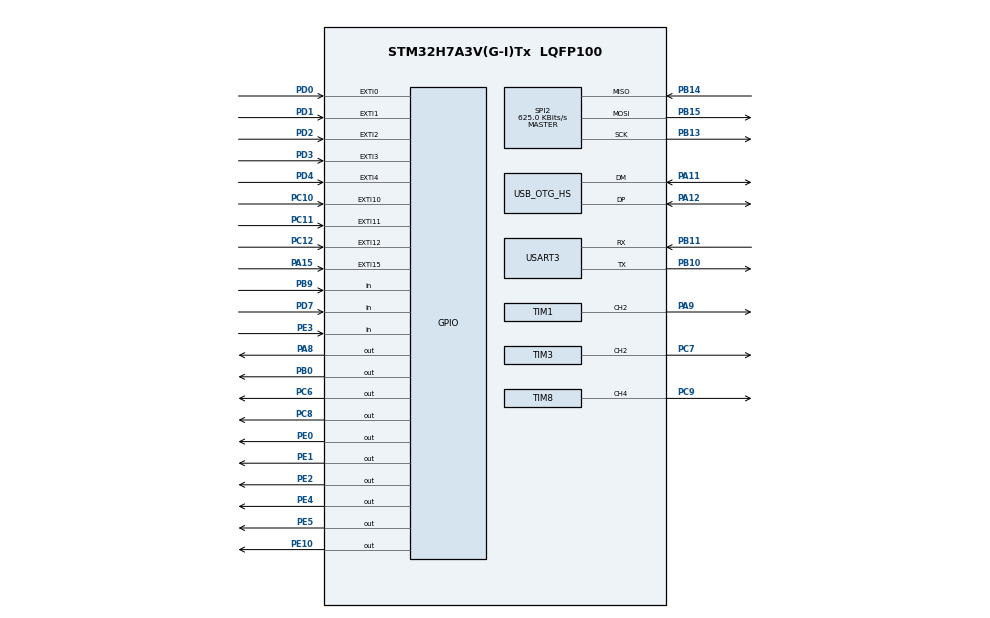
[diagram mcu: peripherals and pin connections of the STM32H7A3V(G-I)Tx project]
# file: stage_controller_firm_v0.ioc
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CORTEX_M7.default_mode_Activation=1
Dma.Request0=TIM1_UP
Dma.Request1=TIM3_UP
Dma.Request2=TIM8_UP
Dma.TIM1_UP.0.Direction=DMA_MEMORY_TO_PERIPH
Dma.TIM1_UP.0.EventEnable=DISABLE
Dma.TIM1_UP.0.FIFOMode=DMA_FIFOMODE_DISABLE
Dma.TIM1_UP.0.Instance=DMA1_Stream0
Dma.TIM1_UP.0.MemDataAlignment=DMA_MDATAALIGN_WORD
Dma.TIM1_UP.0.MemInc=DMA_MINC_ENABLE
Dma.TIM1_UP.0.Mode=DMA_NORMAL
Dma.TIM1_UP.0.PeriphDataAlignment=DMA_PDATAALIGN_WORD
Dma.TIM1_UP.0.PeriphInc=DMA_PINC_DISABLE
Dma.TIM1_UP.0.Polarity=HAL_DMAMUX_REQ_GEN_RISING
Dma.TIM1_UP.0.Priority=DMA_PRIORITY_VERY_HIGH
Dma.TIM1_UP.0.RequestNumber=1
Dma.TIM1_UP.0.SignalID=NONE
Dma.TIM1_UP.0.SyncEnable=DISABLE
Dma.TIM1_UP.0.SyncPolarity=HAL_DMAMUX_SYNC_NO_EVENT
Dma.TIM1_UP.0.SyncRequestNumber=1
Dma.TIM1_UP.0.SyncSignalID=NONE
Dma.TIM3_UP.1.Direction=DMA_MEMORY_TO_PERIPH
Dma.TIM3_UP.1.EventEnable=DISABLE
Dma.TIM3_UP.1.FIFOMode=DMA_FIFOMODE_DISABLE
Dma.TIM3_UP.1.Instance=DMA1_Stream1
Dma.TIM3_UP.1.MemDataAlignment=DMA_MDATAALIGN_WORD
Dma.TIM3_UP.1.MemInc=DMA_MINC_ENABLE
Dma.TIM3_UP.1.Mode=DMA_NORMAL
Dma.TIM3_UP.1.PeriphDataAlignment=DMA_PDATAALIGN_WORD
Dma.TIM3_UP.1.PeriphInc=DMA_PINC_DISABLE
Dma.TIM3_UP.1.Polarity=HAL_DMAMUX_REQ_GEN_RISING
Dma.TIM3_UP.1.Priority=DMA_PRIORITY_VERY_HIGH
Dma.TIM3_UP.1.RequestNumber=1
Dma.TIM3_UP.1.SignalID=NONE
Dma.TIM3_UP.1.SyncEnable=DISABLE
Dma.TIM3_UP.1.SyncPolarity=HAL_DMAMUX_SYNC_NO_EVENT
Dma.TIM3_UP.1.SyncRequestNumber=1
Dma.TIM3_UP.1.SyncSignalID=NONE
Dma.TIM8_UP.2.Direction=DMA_MEMORY_TO_PERIPH
Dma.TIM8_UP.2.EventEnable=DISABLE
Dma.TIM8_UP.2.FIFOMode=DMA_FIFOMODE_DISABLE
Dma.TIM8_UP.2.Instance=DMA1_Stream2
Dma.TIM8_UP.2.MemDataAlignment=DMA_MDATAALIGN_WORD
Dma.TIM8_UP.2.MemInc=DMA_MINC_ENABLE
Dma.TIM8_UP.2.Mode=DMA_NORMAL
Dma.TIM8_UP.2.PeriphDataAlignment=DMA_PDATAALIGN_WORD
Dma.TIM8_UP.2.PeriphInc=DMA_PINC_DISABLE
Dma.TIM8_UP.2.Polarity=HAL_DMAMUX_REQ_GEN_RISING
Dma.TIM8_UP.2.Priority=DMA_PRIORITY_VERY_HIGH
Dma.TIM8_UP.2.RequestNumber=1
Dma.TIM8_UP.2.SignalID=NONE
Dma.TIM8_UP.2.SyncEnable=DISABLE
Dma.TIM8_UP.2.SyncPolarity=HAL_DMAMUX_SYNC_NO_EVENT
Dma.TIM8_UP.2.SyncRequestNumber=1
Dma.TIM8_UP.2.SyncSignalID=NONE
Mcu.Family=STM32H7
Mcu.Name=STM32H7A3V(G-I)Tx
Mcu.Package=LQFP100
NVIC.DMA1_Stream0_IRQn=true\:2\:0\:true\:false\:true\:false\:true\:true
NVIC.DMA1_Stream1_IRQn=true\:2\:0\:true\:false\:true\:false\:true\:true
NVIC.DMA1_Stream2_IRQn=true\:2\:0\:true\:false\:true\:false\:true\:true
NVIC.EXTI0_IRQn=true\:1\:0\:true\:false\:true\:true\:true\:true
NVIC.EXTI15_10_IRQn=true\:1\:0\:true\:false\:true\:true\:true\:true
NVIC.EXTI1_IRQn=true\:1\:0\:true\:false\:true\:true\:true\:true
NVIC.EXTI2_IRQn=true\:1\:0\:true\:false\:true\:true\:true\:true
NVIC.EXTI3_IRQn=true\:1\:0\:true\:false\:true\:true\:true\:true
NVIC.EXTI4_IRQn=true\:1\:0\:true\:false\:true\:true\:true\:true
NVIC.OTG_HS_IRQn=true\:0\:0\:false\:false\:true\:false\:true\:true
NVIC.PriorityGroup=NVIC_PRIORITYGROUP_4
NVIC.TIM1_UP_IRQn=true\:2\:0\:true\:false\:true\:true\:true\:true
NVIC.TIM3_IRQn=true\:2\:0\:true\:false\:true\:true\:true\:true
NVIC.TIM6_DAC_IRQn=true\:3\:0\:true\:false\:true\:true\:true\:true
NVIC.TIM8_UP_TIM13_IRQn=true\:2\:0\:true\:false\:true\:true\:true\:true
NVIC.USART3_IRQn=true\:7\:0\:true\:false\:true\:true\:true\:true
PA11.Mode=Device_Only_FS
PA11.Signal=USB_OTG_HS_DM
PA12.Mode=Device_Only_FS
PA12.Signal=USB_OTG_HS_DP
PA13.Mode=Serial_Wire
PA13.Signal=DEBUG_JTMS-SWDIO
PA14.Mode=Serial_Wire
PA14.Signal=DEBUG_JTCK-SWCLK
PA15.GPIO_ModeDefaultEXTI=GPIO_MODE_IT_RISING_FALLING
PA15.GPIO_PuPd=GPIO_PULLUP
PA15.Signal=GPXTI15
PA8.Signal=GPIO_Output
PA9.Signal=S_TIM1_CH2
PB0.Signal=GPIO_Output
PB10.Mode=Asynchronous
PB10.Signal=USART3_TX
PB11.Mode=Asynchronous
PB11.Signal=USART3_RX
PB13.Mode=Full_Duplex_Master
PB13.Signal=SPI2_SCK
PB14.Mode=Full_Duplex_Master
PB14.Signal=SPI2_MISO
PB15.Mode=Full_Duplex_Master
PB15.Signal=SPI2_MOSI
PB9.Signal=GPIO_Input
PC10.GPIO_ModeDefaultEXTI=GPIO_MODE_IT_RISING_FALLING
PC10.GPIO_PuPd=GPIO_PULLUP
PC10.Signal=GPXTI10
PC11.GPIO_ModeDefaultEXTI=GPIO_MODE_IT_RISING_FALLING
PC11.GPIO_PuPd=GPIO_PULLUP
PC11.Signal=GPXTI11
PC12.GPIO_ModeDefaultEXTI=GPIO_MODE_IT_RISING_FALLING
PC12.GPIO_PuPd=GPIO_PULLUP
PC12.Signal=GPXTI12
PC6.Signal=GPIO_Output
PC7.Signal=S_TIM3_CH2
PC8.Signal=GPIO_Output
PC9.Signal=S_TIM8_CH4
PD0.GPIO_ModeDefaultEXTI=GPIO_MODE_IT_RISING_FALLING
PD0.GPIO_PuPd=GPIO_PULLUP
PD0.Signal=GPXTI0
PD1.GPIO_ModeDefaultEXTI=GPIO_MODE_IT_RISING_FALLING
PD1.GPIO_PuPd=GPIO_PULLUP
PD1.Signal=GPXTI1
PD2.GPIO_ModeDefaultEXTI=GPIO_MODE_IT_RISING_FALLING
PD2.GPIO_PuPd=GPIO_PULLUP
PD2.Signal=GPXTI2
PD3.GPIO_ModeDefaultEXTI=GPIO_MODE_IT_RISING_FALLING
PD3.GPIO_PuPd=GPIO_PULLUP
PD3.Signal=GPXTI3
PD4.GPIO_ModeDefaultEXTI=GPIO_MODE_IT_RISING_FALLING
PD4.GPIO_PuPd=GPIO_PULLUP
PD4.Signal=GPXTI4
PD7.Signal=GPIO_Input
PE0.Signal=GPIO_Output
PE1.Signal=GPIO_Output
PE10.Signal=GPIO_Output
PE2.Signal=GPIO_Output
PE3.Signal=GPIO_Input
PE4.Signal=GPIO_Output
PE5.Signal=GPIO_Output
PH0-OSC_IN.Mode=HSE-External-Clock-Source
PH0-OSC_IN.Signal=RCC_OSC_IN
ProjectManager.HeapSize=0x200
ProjectManager.StackSize=0x400
ProjectManager.TargetToolchain=STM32CubeIDE
RCC.ADCFreq_Value=50390625
RCC.APB1Freq_Value=140000000
RCC.APB2Freq_Value=140000000
RCC.APB3Freq_Value=140000000
RCC.APB4Freq_Value=140000000
RCC.CDPPRE=RCC_APB3_DIV2
RCC.CDPPRE1=RCC_APB1_DIV2
RCC.CDPPRE2=RCC_APB2_DIV2
RCC.CortexFreq_Value=280000000
RCC.DIVM1=5
RCC.DIVN1=112
RCC.DIVQ1=14
RCC.HCLKFreq_Value=280000000
RCC.HSE_VALUE=25000000
RCC.PLLSourceVirtual=RCC_PLLSOURCE_HSE
RCC.SRDPPRE=RCC_APB4_DIV2
RCC.SYSCLKFreq_VALUE=280000000
RCC.SYSCLKSource=RCC_SYSCLKSOURCE_PLLCLK
RCC.USBCLockSelection=RCC_USBCLKSOURCE_HSI48
RCC.USBFreq_Value=48000000
SH.S_TIM1_CH2.0=TIM1_CH2,PWM Generation2 CH2
SH.S_TIM3_CH2.0=TIM3_CH2,PWM Generation2 CH2
SH.S_TIM8_CH4.0=TIM8_CH4,PWM Generation4 CH4
SPI2.BaudRatePrescaler=SPI_BAUDRATEPRESCALER_64
SPI2.CLKPhase=SPI_PHASE_2EDGE
SPI2.CLKPolarity=SPI_POLARITY_HIGH
SPI2.CalculateBaudRate=625.0 KBits/s
SPI2.DataSize=SPI_DATASIZE_8BIT
SPI2.Direction=SPI_DIRECTION_2LINES
SPI2.Mode=SPI_MODE_MASTER
SPI2.VirtualType=VM_MASTER
TIM1.Channel-PWM\ Generation2\ CH2=TIM_CHANNEL_2
TIM1.Prescaler=279
TIM1.TIM_MasterSlaveMode=TIM_MASTERSLAVEMODE_DISABLE
TIM3.Channel-PWM\ Generation2\ CH2=TIM_CHANNEL_2
TIM3.Prescaler=139
TIM8.Channel-PWM\ Generation4\ CH4=TIM_CHANNEL_4
TIM8.Prescaler=279
USART3.VirtualMode-Asynchronous=VM_ASYNC
USB_DEVICE.CLASS_NAME_HS=CDC
USB_DEVICE.VirtualMode=Cdc
USB_DEVICE.VirtualModeHS=Cdc_HS
USB_OTG_HS.VirtualMode-Device_Only_FS=Device_Only_FS
VP_MEMORYMAP_VS_MEMORYMAP.Mode=CurAppReg
VP_TIM1_VS_ClockSourceINT.Mode=Internal
VP_TIM3_VS_ClockSourceINT.Mode=Internal
VP_TIM6_VS_ClockSourceINT.Mode=Enable_Timer
VP_TIM8_VS_ClockSourceINT.Mode=Internal
VP_USB_DEVICE_VS_USB_DEVICE_CDC_HS.Mode=CDC_HS
board=custom

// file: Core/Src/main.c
/* USER CODE BEGIN Header */
/**
  ******************************************************************************
  * @file           : main.c
  * @brief          : Main program body
  ******************************************************************************
  * @attention
  *
  * Copyright (c) 2026 STMicroelectronics.
  * All rights reserved.
  *
  * This software is licensed under terms that can be found in the LICENSE file
  * in the root directory of this software component.
  * If no LICENSE file comes with this software, it is provided AS-IS.
  *
  ******************************************************************************
  */
/* USER CODE END Header */
#include "main.h"
#include "usb_device.h"

/* USER CODE BEGIN Includes */
#include "functions.h"
#include "mtd415t.h"
/* USER CODE END Includes */

SPI_HandleTypeDef hspi2;

TIM_HandleTypeDef htim1;
TIM_HandleTypeDef htim3;
TIM_HandleTypeDef htim6;
TIM_HandleTypeDef htim8;
DMA_HandleTypeDef hdma_tim1_up;
DMA_HandleTypeDef hdma_tim3_up;
DMA_HandleTypeDef hdma_tim8_up;

UART_HandleTypeDef huart3;

void SystemClock_Config(void);
static void MPU_Config(void);
static void MX_GPIO_Init(void);
static void MX_DMA_Init(void);
static void MX_SPI2_Init(void);
static void MX_TIM1_Init(void);
static void MX_TIM3_Init(void);
static void MX_TIM8_Init(void);
static void MX_TIM6_Init(void);
static void MX_USART3_UART_Init(void);

int main(void)
{

  /* MPU Configuration--------------------------------------------------------*/
  MPU_Config();

  /* MCU Configuration--------------------------------------------------------*/

  /* Reset of all peripherals, Initializes the Flash interface and the Systick. */
  HAL_Init();

  /* Configure the system clock */
  SystemClock_Config();

  /* Initialize all configured peripherals */
  MX_GPIO_Init();
  MX_DMA_Init();
  MX_SPI2_Init();
  MX_TIM1_Init();
  MX_TIM3_Init();
  MX_USB_DEVICE_Init();
  MX_TIM8_Init();
  MX_TIM6_Init();
  MX_USART3_UART_Init();
  /* USER CODE BEGIN 2 */

  Motor_Init();
  GetCLK();

  /* MTD415T TEC controller: bind USART3 and start interrupt RX.
   * Requires USART3 to be enabled in CubeMX (115200-8-N-1, global IRQ on),
   * which generates `huart3` and MX_USART3_UART_Init() above. */
  MTD415T_Init(&huart3);

  /* ── Parameter initialisation ──
   * 1. Reg_prepare() fills parm[] with names and default values.
   * 2. Parm_Flash_Load() overwrites parm[] with saved data when valid.
   *    If flash is blank or corrupt the defaults from Reg_prepare() remain.
   * 3. Parm_set() always runs, applying whichever values are in parm[].
   */
  Reg_prepare();
  (void)Parm_Flash_Load();
  Parm_set();

  /* ── TIM6: 10 ms tick  (APB1 timer = 140 MHz, PSC=1399, ARR=999 → 100 Hz) */
  htim6.Instance->PSC = 1399u;
  htim6.Instance->ARR = 999u;
  htim6.Instance->EGR = TIM_EGR_UG;

  /* NVIC は CubeMX で設定（DMA1_Stream0/1/2, TIM1_UP, TIM8_UP_TIM13, TIM3, TIM6_DAC,
   * EXTI）。ここでは TIM6 の更新割り込みを開始するのみ。*/
  HAL_TIM_Base_Start_IT(&htim6);

  /* USER CODE END 2 */

  /* Infinite loop */
  while (1)
  {

    /* USER CODE BEGIN 3 */
    Cmd_Process();
  }
  /* USER CODE END 3 */
}

void SystemClock_Config(void)
{
  RCC_OscInitTypeDef RCC_OscInitStruct = {0};
  RCC_ClkInitTypeDef RCC_ClkInitStruct = {0};

  /*AXI clock gating */
  RCC->CKGAENR = 0xE003FFFF;

  /** Supply configuration update enable
  */
  HAL_PWREx_ConfigSupply(PWR_LDO_SUPPLY);

  /** Configure the main internal regulator output voltage
  */
  __HAL_PWR_VOLTAGESCALING_CONFIG(PWR_REGULATOR_VOLTAGE_SCALE0);

  while(!__HAL_PWR_GET_FLAG(PWR_FLAG_VOSRDY)) {}

  /** Initializes the RCC Oscillators according to the specified parameters
  * in the RCC_OscInitTypeDef structure.
  */
  RCC_OscInitStruct.OscillatorType = RCC_OSCILLATORTYPE_HSI48|RCC_OSCILLATORTYPE_HSE;
  RCC_OscInitStruct.HSEState = RCC_HSE_BYPASS;
  RCC_OscInitStruct.HSI48State = RCC_HSI48_ON;
  RCC_OscInitStruct.PLL.PLLState = RCC_PLL_ON;
  RCC_OscInitStruct.PLL.PLLSource = RCC_PLLSOURCE_HSE;
  RCC_OscInitStruct.PLL.PLLM = 5;
  RCC_OscInitStruct.PLL.PLLN = 112;
  RCC_OscInitStruct.PLL.PLLP = 2;
  RCC_OscInitStruct.PLL.PLLQ = 14;
  RCC_OscInitStruct.PLL.PLLR = 2;
  RCC_OscInitStruct.PLL.PLLRGE = RCC_PLL1VCIRANGE_2;
  RCC_OscInitStruct.PLL.PLLVCOSEL = RCC_PLL1VCOWIDE;
  RCC_OscInitStruct.PLL.PLLFRACN = 0;
  if (HAL_RCC_OscConfig(&RCC_OscInitStruct) != HAL_OK)
  {
    Error_Handler();
  }

  /** Initializes the CPU, AHB and APB buses clocks
  */
  RCC_ClkInitStruct.ClockType = RCC_CLOCKTYPE_HCLK|RCC_CLOCKTYPE_SYSCLK
                              |RCC_CLOCKTYPE_PCLK1|RCC_CLOCKTYPE_PCLK2
                              |RCC_CLOCKTYPE_D3PCLK1|RCC_CLOCKTYPE_D1PCLK1;
  RCC_ClkInitStruct.SYSCLKSource = RCC_SYSCLKSOURCE_PLLCLK;
  RCC_ClkInitStruct.SYSCLKDivider = RCC_SYSCLK_DIV1;
  RCC_ClkInitStruct.AHBCLKDivider = RCC_HCLK_DIV1;
  RCC_ClkInitStruct.APB3CLKDivider = RCC_APB3_DIV2;
  RCC_ClkInitStruct.APB1CLKDivider = RCC_APB1_DIV2;
  RCC_ClkInitStruct.APB2CLKDivider = RCC_APB2_DIV2;
  RCC_ClkInitStruct.APB4CLKDivider = RCC_APB4_DIV2;

  if (HAL_RCC_ClockConfig(&RCC_ClkInitStruct, FLASH_LATENCY_6) != HAL_OK)
  {
    Error_Handler();
  }
}

static void MX_SPI2_Init(void)
{

  /* SPI2 parameter configuration*/
  hspi2.Instance = SPI2;
  hspi2.Init.Mode = SPI_MODE_MASTER;
  hspi2.Init.Direction = SPI_DIRECTION_2LINES;
  hspi2.Init.DataSize = SPI_DATASIZE_8BIT;
  hspi2.Init.CLKPolarity = SPI_POLARITY_HIGH;
  hspi2.Init.CLKPhase = SPI_PHASE_2EDGE;
  hspi2.Init.NSS = SPI_NSS_SOFT;
  hspi2.Init.BaudRatePrescaler = SPI_BAUDRATEPRESCALER_64;
  hspi2.Init.FirstBit = SPI_FIRSTBIT_MSB;
  hspi2.Init.TIMode = SPI_TIMODE_DISABLE;
  hspi2.Init.CRCCalculation = SPI_CRCCALCULATION_DISABLE;
  hspi2.Init.CRCPolynomial = 0x0;
  hspi2.Init.NSSPMode = SPI_NSS_PULSE_ENABLE;
  hspi2.Init.NSSPolarity = SPI_NSS_POLARITY_LOW;
  hspi2.Init.FifoThreshold = SPI_FIFO_THRESHOLD_01DATA;
  hspi2.Init.TxCRCInitializationPattern = SPI_CRC_INITIALIZATION_ALL_ZERO_PATTERN;
  hspi2.Init.RxCRCInitializationPattern = SPI_CRC_INITIALIZATION_ALL_ZERO_PATTERN;
  hspi2.Init.MasterSSIdleness = SPI_MASTER_SS_IDLENESS_00CYCLE;
  hspi2.Init.MasterInterDataIdleness = SPI_MASTER_INTERDATA_IDLENESS_00CYCLE;
  hspi2.Init.MasterReceiverAutoSusp = SPI_MASTER_RX_AUTOSUSP_DISABLE;
  hspi2.Init.MasterKeepIOState = SPI_MASTER_KEEP_IO_STATE_DISABLE;
  hspi2.Init.IOSwap = SPI_IO_SWAP_DISABLE;
  if (HAL_SPI_Init(&hspi2) != HAL_OK)
  {
    Error_Handler();
  }

}

static void MX_TIM1_Init(void)
{

  TIM_ClockConfigTypeDef sClockSourceConfig = {0};
  TIM_MasterConfigTypeDef sMasterConfig = {0};
  TIM_OC_InitTypeDef sConfigOC = {0};
  TIM_BreakDeadTimeConfigTypeDef sBreakDeadTimeConfig = {0};

  htim1.Instance = TIM1;
  htim1.Init.Prescaler = 279;
  htim1.Init.CounterMode = TIM_COUNTERMODE_UP;
  htim1.Init.Period = 65535;
  htim1.Init.ClockDivision = TIM_CLOCKDIVISION_DIV1;
  htim1.Init.RepetitionCounter = 0;
  htim1.Init.AutoReloadPreload = TIM_AUTORELOAD_PRELOAD_DISABLE;
  if (HAL_TIM_Base_Init(&htim1) != HAL_OK)
  {
    Error_Handler();
  }
  sClockSourceConfig.ClockSource = TIM_CLOCKSOURCE_INTERNAL;
  if (HAL_TIM_ConfigClockSource(&htim1, &sClockSourceConfig) != HAL_OK)
  {
    Error_Handler();
  }
  if (HAL_TIM_PWM_Init(&htim1) != HAL_OK)
  {
    Error_Handler();
  }
  sMasterConfig.MasterOutputTrigger = TIM_TRGO_RESET;
  sMasterConfig.MasterOutputTrigger2 = TIM_TRGO2_RESET;
  sMasterConfig.MasterSlaveMode = TIM_MASTERSLAVEMODE_DISABLE;
  if (HAL_TIMEx_MasterConfigSynchronization(&htim1, &sMasterConfig) != HAL_OK)
  {
    Error_Handler();
  }
  sConfigOC.OCMode = TIM_OCMODE_PWM1;
  sConfigOC.Pulse = 0;
  sConfigOC.OCPolarity = TIM_OCPOLARITY_HIGH;
  sConfigOC.OCNPolarity = TIM_OCNPOLARITY_HIGH;
  sConfigOC.OCFastMode = TIM_OCFAST_DISABLE;
  sConfigOC.OCIdleState = TIM_OCIDLESTATE_RESET;
  sConfigOC.OCNIdleState = TIM_OCNIDLESTATE_RESET;
  if (HAL_TIM_PWM_ConfigChannel(&htim1, &sConfigOC, TIM_CHANNEL_2) != HAL_OK)
  {
    Error_Handler();
  }
  sBreakDeadTimeConfig.OffStateRunMode = TIM_OSSR_DISABLE;
  sBreakDeadTimeConfig.OffStateIDLEMode = TIM_OSSI_DISABLE;
  sBreakDeadTimeConfig.LockLevel = TIM_LOCKLEVEL_OFF;
  sBreakDeadTimeConfig.DeadTime = 0;
  sBreakDeadTimeConfig.BreakState = TIM_BREAK_DISABLE;
  sBreakDeadTimeConfig.BreakPolarity = TIM_BREAKPOLARITY_HIGH;
  sBreakDeadTimeConfig.BreakFilter = 0;
  sBreakDeadTimeConfig.Break2State = TIM_BREAK2_DISABLE;
  sBreakDeadTimeConfig.Break2Polarity = TIM_BREAK2POLARITY_HIGH;
  sBreakDeadTimeConfig.Break2Filter = 0;
  sBreakDeadTimeConfig.AutomaticOutput = TIM_AUTOMATICOUTPUT_DISABLE;
  if (HAL_TIMEx_ConfigBreakDeadTime(&htim1, &sBreakDeadTimeConfig) != HAL_OK)
  {
    Error_Handler();
  }
  HAL_TIM_MspPostInit(&htim1);

}

static void MX_TIM3_Init(void)
{

  TIM_ClockConfigTypeDef sClockSourceConfig = {0};
  TIM_MasterConfigTypeDef sMasterConfig = {0};
  TIM_OC_InitTypeDef sConfigOC = {0};

  htim3.Instance = TIM3;
  htim3.Init.Prescaler = 139;
  htim3.Init.CounterMode = TIM_COUNTERMODE_UP;
  htim3.Init.Period = 65535;
  htim3.Init.ClockDivision = TIM_CLOCKDIVISION_DIV1;
  htim3.Init.AutoReloadPreload = TIM_AUTORELOAD_PRELOAD_DISABLE;
  if (HAL_TIM_Base_Init(&htim3) != HAL_OK)
  {
    Error_Handler();
  }
  sClockSourceConfig.ClockSource = TIM_CLOCKSOURCE_INTERNAL;
  if (HAL_TIM_ConfigClockSource(&htim3, &sClockSourceConfig) != HAL_OK)
  {
    Error_Handler();
  }
  if (HAL_TIM_PWM_Init(&htim3) != HAL_OK)
  {
    Error_Handler();
  }
  sMasterConfig.MasterOutputTrigger = TIM_TRGO_RESET;
  sMasterConfig.MasterSlaveMode = TIM_MASTERSLAVEMODE_DISABLE;
  if (HAL_TIMEx_MasterConfigSynchronization(&htim3, &sMasterConfig) != HAL_OK)
  {
    Error_Handler();
  }
  sConfigOC.OCMode = TIM_OCMODE_PWM1;
  sConfigOC.Pulse = 0;
  sConfigOC.OCPolarity = TIM_OCPOLARITY_HIGH;
  sConfigOC.OCFastMode = TIM_OCFAST_DISABLE;
  if (HAL_TIM_PWM_ConfigChannel(&htim3, &sConfigOC, TIM_CHANNEL_2) != HAL_OK)
  {
    Error_Handler();
  }
  HAL_TIM_MspPostInit(&htim3);

}

static void MX_TIM6_Init(void)
{

  TIM_MasterConfigTypeDef sMasterConfig = {0};

  htim6.Instance = TIM6;
  htim6.Init.Prescaler = 0;
  htim6.Init.CounterMode = TIM_COUNTERMODE_UP;
  htim6.Init.Period = 65535;
  htim6.Init.AutoReloadPreload = TIM_AUTORELOAD_PRELOAD_DISABLE;
  if (HAL_TIM_Base_Init(&htim6) != HAL_OK)
  {
    Error_Handler();
  }
  sMasterConfig.MasterOutputTrigger = TIM_TRGO_RESET;
  sMasterConfig.MasterSlaveMode = TIM_MASTERSLAVEMODE_DISABLE;
  if (HAL_TIMEx_MasterConfigSynchronization(&htim6, &sMasterConfig) != HAL_OK)
  {
    Error_Handler();
  }

}

static void MX_TIM8_Init(void)
{

  TIM_ClockConfigTypeDef sClockSourceConfig = {0};
  TIM_MasterConfigTypeDef sMasterConfig = {0};
  TIM_OC_InitTypeDef sConfigOC = {0};
  TIM_BreakDeadTimeConfigTypeDef sBreakDeadTimeConfig = {0};

  htim8.Instance = TIM8;
  htim8.Init.Prescaler = 279;
  htim8.Init.CounterMode = TIM_COUNTERMODE_UP;
  htim8.Init.Period = 65535;
  htim8.Init.ClockDivision = TIM_CLOCKDIVISION_DIV1;
  htim8.Init.RepetitionCounter = 0;
  htim8.Init.AutoReloadPreload = TIM_AUTORELOAD_PRELOAD_DISABLE;
  if (HAL_TIM_Base_Init(&htim8) != HAL_OK)
  {
    Error_Handler();
  }
  sClockSourceConfig.ClockSource = TIM_CLOCKSOURCE_INTERNAL;
  if (HAL_TIM_ConfigClockSource(&htim8, &sClockSourceConfig) != HAL_OK)
  {
    Error_Handler();
  }
  if (HAL_TIM_PWM_Init(&htim8) != HAL_OK)
  {
    Error_Handler();
  }
  sMasterConfig.MasterOutputTrigger = TIM_TRGO_RESET;
  sMasterConfig.MasterOutputTrigger2 = TIM_TRGO2_RESET;
  sMasterConfig.MasterSlaveMode = TIM_MASTERSLAVEMODE_DISABLE;
  if (HAL_TIMEx_MasterConfigSynchronization(&htim8, &sMasterConfig) != HAL_OK)
  {
    Error_Handler();
  }
  sConfigOC.OCMode = TIM_OCMODE_PWM1;
  sConfigOC.Pulse = 0;
  sConfigOC.OCPolarity = TIM_OCPOLARITY_HIGH;
  sConfigOC.OCFastMode = TIM_OCFAST_DISABLE;
  sConfigOC.OCIdleState = TIM_OCIDLESTATE_RESET;
  sConfigOC.OCNIdleState = TIM_OCNIDLESTATE_RESET;
  if (HAL_TIM_PWM_ConfigChannel(&htim8, &sConfigOC, TIM_CHANNEL_4) != HAL_OK)
  {
    Error_Handler();
  }
  sBreakDeadTimeConfig.OffStateRunMode = TIM_OSSR_DISABLE;
  sBreakDeadTimeConfig.OffStateIDLEMode = TIM_OSSI_DISABLE;
  sBreakDeadTimeConfig.LockLevel = TIM_LOCKLEVEL_OFF;
  sBreakDeadTimeConfig.DeadTime = 0;
  sBreakDeadTimeConfig.BreakState = TIM_BREAK_DISABLE;
  sBreakDeadTimeConfig.BreakPolarity = TIM_BREAKPOLARITY_HIGH;
  sBreakDeadTimeConfig.BreakFilter = 0;
  sBreakDeadTimeConfig.Break2State = TIM_BREAK2_DISABLE;
  sBreakDeadTimeConfig.Break2Polarity = TIM_BREAK2POLARITY_HIGH;
  sBreakDeadTimeConfig.Break2Filter = 0;
  sBreakDeadTimeConfig.AutomaticOutput = TIM_AUTOMATICOUTPUT_DISABLE;
  if (HAL_TIMEx_ConfigBreakDeadTime(&htim8, &sBreakDeadTimeConfig) != HAL_OK)
  {
    Error_Handler();
  }
  HAL_TIM_MspPostInit(&htim8);

}

static void MX_USART3_UART_Init(void)
{

  huart3.Instance = USART3;
  huart3.Init.BaudRate = 115200;
  huart3.Init.WordLength = UART_WORDLENGTH_8B;
  huart3.Init.StopBits = UART_STOPBITS_1;
  huart3.Init.Parity = UART_PARITY_NONE;
  huart3.Init.Mode = UART_MODE_TX_RX;
  huart3.Init.HwFlowCtl = UART_HWCONTROL_NONE;
  huart3.Init.OverSampling = UART_OVERSAMPLING_16;
  huart3.Init.OneBitSampling = UART_ONE_BIT_SAMPLE_DISABLE;
  huart3.Init.ClockPrescaler = UART_PRESCALER_DIV1;
  huart3.AdvancedInit.AdvFeatureInit = UART_ADVFEATURE_NO_INIT;
  if (HAL_UART_Init(&huart3) != HAL_OK)
  {
    Error_Handler();
  }
  if (HAL_UARTEx_SetTxFifoThreshold(&huart3, UART_TXFIFO_THRESHOLD_1_8) != HAL_OK)
  {
    Error_Handler();
  }
  if (HAL_UARTEx_SetRxFifoThreshold(&huart3, UART_RXFIFO_THRESHOLD_1_8) != HAL_OK)
  {
    Error_Handler();
  }
  if (HAL_UARTEx_DisableFifoMode(&huart3) != HAL_OK)
  {
    Error_Handler();
  }

}

static void MX_DMA_Init(void)
{

  /* DMA controller clock enable */
  __HAL_RCC_DMA1_CLK_ENABLE();

  /* DMA interrupt init */
  /* DMA1_Stream0_IRQn interrupt configuration */
  HAL_NVIC_SetPriority(DMA1_Stream0_IRQn, 2, 0);
  HAL_NVIC_EnableIRQ(DMA1_Stream0_IRQn);
  /* DMA1_Stream1_IRQn interrupt configuration */
  HAL_NVIC_SetPriority(DMA1_Stream1_IRQn, 2, 0);
  HAL_NVIC_EnableIRQ(DMA1_Stream1_IRQn);
  /* DMA1_Stream2_IRQn interrupt configuration */
  HAL_NVIC_SetPriority(DMA1_Stream2_IRQn, 2, 0);
  HAL_NVIC_EnableIRQ(DMA1_Stream2_IRQn);

}

static void MX_GPIO_Init(void)
{
  GPIO_InitTypeDef GPIO_InitStruct = {0};

  /* GPIO Ports Clock Enable */
  __HAL_RCC_GPIOE_CLK_ENABLE();
  __HAL_RCC_GPIOH_CLK_ENABLE();
  __HAL_RCC_GPIOB_CLK_ENABLE();
  __HAL_RCC_GPIOC_CLK_ENABLE();
  __HAL_RCC_GPIOA_CLK_ENABLE();
  __HAL_RCC_GPIOD_CLK_ENABLE();

  /*Configure GPIO pin Output Level */
  HAL_GPIO_WritePin(GPIOE, GPIO_PIN_2|GPIO_PIN_4|GPIO_PIN_5|GPIO_PIN_10
                          |GPIO_PIN_0|GPIO_PIN_1, GPIO_PIN_RESET);

  /*Configure GPIO pin Output Level */
  HAL_GPIO_WritePin(GPIOB, GPIO_PIN_0, GPIO_PIN_RESET);

  /*Configure GPIO pin Output Level */
  HAL_GPIO_WritePin(GPIOC, GPIO_PIN_6|GPIO_PIN_8, GPIO_PIN_RESET);

  /*Configure GPIO pin Output Level */
  HAL_GPIO_WritePin(GPIOA, GPIO_PIN_8, GPIO_PIN_RESET);

  /*Configure GPIO pins : PE2 PE4 PE5 PE10
                           PE0 PE1 */
  GPIO_InitStruct.Pin = GPIO_PIN_2|GPIO_PIN_4|GPIO_PIN_5|GPIO_PIN_10
                          |GPIO_PIN_0|GPIO_PIN_1;
  GPIO_InitStruct.Mode = GPIO_MODE_OUTPUT_PP;
  GPIO_InitStruct.Pull = GPIO_NOPULL;
  GPIO_InitStruct.Speed = GPIO_SPEED_FREQ_LOW;
  HAL_GPIO_Init(GPIOE, &GPIO_InitStruct);

  /*Configure GPIO pin : PE3 */
  GPIO_InitStruct.Pin = GPIO_PIN_3;
  GPIO_InitStruct.Mode = GPIO_MODE_INPUT;
  GPIO_InitStruct.Pull = GPIO_NOPULL;
  HAL_GPIO_Init(GPIOE, &GPIO_InitStruct);

  /*Configure GPIO pin : PB0 */
  GPIO_InitStruct.Pin = GPIO_PIN_0;
  GPIO_InitStruct.Mode = GPIO_MODE_OUTPUT_PP;
  GPIO_InitStruct.Pull = GPIO_NOPULL;
  GPIO_InitStruct.Speed = GPIO_SPEED_FREQ_LOW;
  HAL_GPIO_Init(GPIOB, &GPIO_InitStruct);

  /*Configure GPIO pins : PC6 PC8 */
  GPIO_InitStruct.Pin = GPIO_PIN_6|GPIO_PIN_8;
  GPIO_InitStruct.Mode = GPIO_MODE_OUTPUT_PP;
  GPIO_InitStruct.Pull = GPIO_NOPULL;
  GPIO_InitStruct.Speed = GPIO_SPEED_FREQ_LOW;
  HAL_GPIO_Init(GPIOC, &GPIO_InitStruct);

  /*Configure GPIO pin : PA8 */
  GPIO_InitStruct.Pin = GPIO_PIN_8;
  GPIO_InitStruct.Mode = GPIO_MODE_OUTPUT_PP;
  GPIO_InitStruct.Pull = GPIO_NOPULL;
  GPIO_InitStruct.Speed = GPIO_SPEED_FREQ_LOW;
  HAL_GPIO_Init(GPIOA, &GPIO_InitStruct);

  /*Configure GPIO pin : PA15 */
  GPIO_InitStruct.Pin = GPIO_PIN_15;
  GPIO_InitStruct.Mode = GPIO_MODE_IT_RISING_FALLING;
  GPIO_InitStruct.Pull = GPIO_PULLUP;
  HAL_GPIO_Init(GPIOA, &GPIO_InitStruct);

  /*Configure GPIO pins : PC10 PC11 PC12 */
  GPIO_InitStruct.Pin = GPIO_PIN_10|GPIO_PIN_11|GPIO_PIN_12;
  GPIO_InitStruct.Mode = GPIO_MODE_IT_RISING_FALLING;
  GPIO_InitStruct.Pull = GPIO_PULLUP;
  HAL_GPIO_Init(GPIOC, &GPIO_InitStruct);

  /*Configure GPIO pins : PD0 PD1 PD2 PD3
                           PD4 */
  GPIO_InitStruct.Pin = GPIO_PIN_0|GPIO_PIN_1|GPIO_PIN_2|GPIO_PIN_3
                          |GPIO_PIN_4;
  GPIO_InitStruct.Mode = GPIO_MODE_IT_RISING_FALLING;
  GPIO_InitStruct.Pull = GPIO_PULLUP;
  HAL_GPIO_Init(GPIOD, &GPIO_InitStruct);

  /*Configure GPIO pin : PD7 */
  GPIO_InitStruct.Pin = GPIO_PIN_7;
  GPIO_InitStruct.Mode = GPIO_MODE_INPUT;
  GPIO_InitStruct.Pull = GPIO_NOPULL;
  HAL_GPIO_Init(GPIOD, &GPIO_InitStruct);

  /*Configure GPIO pin : PB9 */
  GPIO_InitStruct.Pin = GPIO_PIN_9;
  GPIO_InitStruct.Mode = GPIO_MODE_INPUT;
  GPIO_InitStruct.Pull = GPIO_NOPULL;
  HAL_GPIO_Init(GPIOB, &GPIO_InitStruct);

  /* EXTI interrupt init*/
  HAL_NVIC_SetPriority(EXTI0_IRQn, 1, 0);
  HAL_NVIC_EnableIRQ(EXTI0_IRQn);

  HAL_NVIC_SetPriority(EXTI1_IRQn, 1, 0);
  HAL_NVIC_EnableIRQ(EXTI1_IRQn);

  HAL_NVIC_SetPriority(EXTI2_IRQn, 1, 0);
  HAL_NVIC_EnableIRQ(EXTI2_IRQn);

  HAL_NVIC_SetPriority(EXTI3_IRQn, 1, 0);
  HAL_NVIC_EnableIRQ(EXTI3_IRQn);

  HAL_NVIC_SetPriority(EXTI4_IRQn, 1, 0);
  HAL_NVIC_EnableIRQ(EXTI4_IRQn);

  HAL_NVIC_SetPriority(EXTI15_10_IRQn, 1, 0);
  HAL_NVIC_EnableIRQ(EXTI15_10_IRQn);

}

 /* MPU Configuration */

void MPU_Config(void)
{
  MPU_Region_InitTypeDef MPU_InitStruct = {0};

  /* Disables the MPU */
  HAL_MPU_Disable();

  /** Initializes and configures the Region and the memory to be protected
  */
  MPU_InitStruct.Enable = MPU_REGION_ENABLE;
  MPU_InitStruct.Number = MPU_REGION_NUMBER0;
  MPU_InitStruct.BaseAddress = 0x0;
  MPU_InitStruct.Size = MPU_REGION_SIZE_4GB;
  MPU_InitStruct.SubRegionDisable = 0x87;
  MPU_InitStruct.TypeExtField = MPU_TEX_LEVEL0;
  MPU_InitStruct.AccessPermission = MPU_REGION_NO_ACCESS;
  MPU_InitStruct.DisableExec = MPU_INSTRUCTION_ACCESS_DISABLE;
  MPU_InitStruct.IsShareable = MPU_ACCESS_SHAREABLE;
  MPU_InitStruct.IsCacheable = MPU_ACCESS_NOT_CACHEABLE;
  MPU_InitStruct.IsBufferable = MPU_ACCESS_NOT_BUFFERABLE;

  HAL_MPU_ConfigRegion(&MPU_InitStruct);
  /* Enables the MPU */
  HAL_MPU_Enable(MPU_PRIVILEGED_DEFAULT);

}

void Error_Handler(void)
{
  __disable_irq();
  while (1)
  {
  }
}
